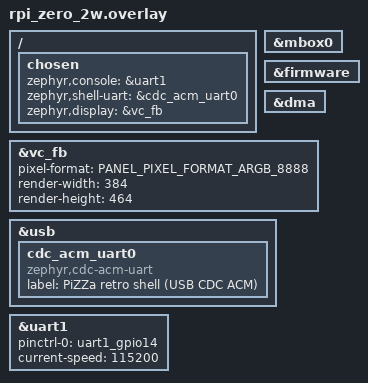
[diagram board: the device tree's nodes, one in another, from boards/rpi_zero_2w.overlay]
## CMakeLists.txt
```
# SPDX-License-Identifier: Apache-2.0
#
# PiZZa -- libretro frontend (apps/retro).
#
# A nanoarch-class libretro frontend over the sdl2shim seams: the 6
# libretro callbacks map onto s2s_present_* / s2s_audio_* / the shim
# event queue, and the core is (for M0) statically linked into the
# image -- the RetroArch console fused-binary model. llext-loaded
# cores arrive at M2.
#
# Core: libretro-2048 (public domain), consumed as an untouched
# upstream tree via the LIBRETRO_2048_SRC_DIR env, like minivmac's
# MINIVMAC_SRC_DIR. Pure C -- no C++ toolchain flags needed.

cmake_minimum_required(VERSION 3.20.0)

find_package(Zephyr REQUIRED HINTS $ENV{ZEPHYR_BASE})
project(pizza_retro LANGUAGES C)

# sample_usbd helper for the USB CDC ACM shell on hardware boards.
if(CONFIG_USB_DEVICE_STACK_NEXT)
  include(${ZEPHYR_BASE}/samples/subsys/usb/common/common.cmake)
endif()

if(NOT DEFINED ENV{LIBRETRO_2048_SRC_DIR})
  message(FATAL_ERROR
    "retro: set LIBRETRO_2048_SRC_DIR to a libretro-2048 checkout "
    "(git clone https://github.com/libretro/libretro-2048)")
endif()
set(CORE_DIR $ENV{LIBRETRO_2048_SRC_DIR})

# The non-cairo software renderer build: 3 TUs, XRGB8888.
set(RETRO_CORE_SRC
  ${CORE_DIR}/libretro.c
  ${CORE_DIR}/game_noncairo.c
  ${CORE_DIR}/game_shared.c
)

# ── shared shim (apps/lib/sdl2shim): CORE group only ────────────────
# The frontend makes no SDL draw calls; it consumes the event queue
# (SDL_PollEvent/SDL_GetKeyboardState) so every existing input
# producer (scripted, CDC shell, btinput) works unchanged.
include(${CMAKE_CURRENT_SOURCE_DIR}/../lib/sdl2shim/sdl2shim.cmake)

set(RETRO_SRC
  src/main.c
  src/retro_frontend.c
  src/retro_vfs_stubs.c
  ${SDL2SHIM_CORE_SOURCES}
)

# Audio backend (lib-owned). 2048 emits no audio; shim_stub.c still
# delegates to the s2s_audio_* seam, so a backend TU must link.
if(CONFIG_SDL2SHIM_AUDIO_HDMI)
  list(APPEND RETRO_SRC ${SDL2SHIM_AUDIO_HDMI_SOURCES})
else()
  list(APPEND RETRO_SRC ${SDL2SHIM_AUDIO_NONE})
endif()

# USB device stack bring-up (lib).
if(CONFIG_USB_DEVICE_STACK_NEXT)
  list(APPEND RETRO_SRC ${SDL2SHIM_USB})
endif()

# `retro` shell command set -- interactive retropad injection over CDC.
if(CONFIG_SHELL)
  list(APPEND RETRO_SRC src/retro_shell.c)
endif()

# Frame present backend (app-local, as for every shim consumer).
if(CONFIG_RETRO_PRESENT_DISPLAY)
  list(APPEND RETRO_SRC src/retro_present_display.c)
elseif(CONFIG_RETRO_PRESENT_SEMIHOST)
  list(APPEND RETRO_SRC src/retro_present_semihost.c)
else()
  list(APPEND RETRO_SRC src/retro_present_none.c)
endif()

# Scripted synthetic input -- title -> game -> moves timeline for the
# qemu sim gate.
if(CONFIG_RETRO_SCRIPTED_INPUT)
  list(APPEND RETRO_SRC src/retro_scripted.c)
endif()

# BT HID input (pad/keyboard) via apps/lib/btinput -- rpi_zero_2w only
# (boards/rpi_zero_2w.conf sets CONFIG_BTINPUT; qemu has no radio).
if(CONFIG_BTINPUT)
  include(${CMAKE_CURRENT_SOURCE_DIR}/../lib/btinput/btinput.cmake)
  # The BT patchram (.hcd) is a gitignored vendor blob (PROVENANCE.md).
  # Fail LOUDLY if missing: an empty-patchram image wedges the controller
  # at runtime (Download_Minidriver with nothing to launch).
  if(NOT CONFIG_AIROC_CUSTOM_FIRMWARE_HCD_BLOB)
    message(FATAL_ERROR
      "retro+BTINPUT: CONFIG_AIROC_CUSTOM_FIRMWARE_HCD_BLOB is unset")
  endif()
  set(_bt_blob "${CONFIG_AIROC_CUSTOM_FIRMWARE_HCD_BLOB}")
  if(NOT IS_ABSOLUTE "${_bt_blob}")
    set(_bt_blob "${CMAKE_CURRENT_SOURCE_DIR}/${_bt_blob}")
  endif()
  if(NOT EXISTS "${_bt_blob}")
    message(FATAL_ERROR
      "retro+BTINPUT: BT patchram not found:\n  ${_bt_blob}\n"
      "It is gitignored (vendor blob) -- fetch it per "
      "apps/lib/btinput/firmware/PROVENANCE.md before building.")
  endif()
  target_sources(app PRIVATE ${BTINPUT_SOURCES} src/retro_btinput.c)
  target_include_directories(app PRIVATE ${BTINPUT_INCLUDE_DIRS})
endif()

target_sources(app PRIVATE
  ${RETRO_CORE_SRC}
  ${RETRO_SRC}
)

target_include_directories(app PRIVATE
  ${SDL2SHIM_INCLUDE_DIRS}
  ${CORE_DIR}
  ${CORE_DIR}/libretro-common/include
  src
)

# The vendored core trips warnings its desktop builds silence.
set_source_files_properties(${RETRO_CORE_SRC} PROPERTIES COMPILE_OPTIONS
  "-Wno-unused-variable;-Wno-unused-parameter;-Wno-missing-field-initializers;-Wno-double-promotion;-Wno-missing-prototypes;-Wno-unused-but-set-variable"
)
```

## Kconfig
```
# SPDX-License-Identifier: Apache-2.0
#
# PiZZa libretro frontend -- app options.

# SAMPLE_USBD_* options for sample_usbd_init.c on boards with the USB
# device stack.
source "samples/subsys/usb/common/Kconfig.sample_usbd"

# Shared shim: audio-backend choice + SDL2SHIM log module.
rsource "../lib/sdl2shim/Kconfig"
# BT HID input (pad/keyboard/mouse) -- enabled per-board (rpi_zero_2w).
rsource "../lib/btinput/Kconfig"

menu "PiZZa libretro frontend"

choice RETRO_CORE_SOURCE
	prompt "libretro core source"
	default RETRO_CORE_STATIC

config RETRO_CORE_STATIC
	bool "Statically linked core (fused binary, RetroArch console model)"

config RETRO_CORE_LLEXT_EMBED
	bool "llext core embedded in the image (buf loader; sim)"
	depends on LLEXT

config RETRO_CORE_LLEXT_FS
	bool "llext core from the filesystem (fs loader; SD card)"
	depends on LLEXT && FILE_SYSTEM

endchoice

config RETRO_CORE_LLEXT_PATH
	string "Filesystem path of the core llext"
	depends on RETRO_CORE_LLEXT_FS
	default "/SD:/cores/2048.llext"

config RETRO_STORAGE_MOUNT
	string "Storage volume the frontend mounts (cores + saves)"
	depends on RETRO_CORE_LLEXT_FS
	default "/SD:"

config RETRO_MENU
	bool "Launcher menu (scan a cores dir, pick + swap in-process)"
	depends on RETRO_CORE_LLEXT_FS
	default y
	help
	  M4: on boot show a picker of the *.llext cores in
	  RETRO_MENU_DIR; launching one binds + runs it; the L+R pad
	  chord or `retro menu` tears it down and returns to the picker.
	  Without this the frontend runs the single RETRO_CORE_LLEXT_PATH
	  core forever (M3 behavior).

config RETRO_MENU_DIR
	string "Directory scanned for core llext files"
	depends on RETRO_MENU
	default "/SD:/cores"

config RETRO_MENU_WIDTH
	int "Launcher render width (match the board's virtual FB)"
	depends on RETRO_MENU
	default 640

config RETRO_MENU_HEIGHT
	int "Launcher render height (match the board's virtual FB)"
	depends on RETRO_MENU
	default 480

config RETRO_QEMU_RAMDISK_SEED
	bool "Seed the qemu ram-disk with embedded cores (sim menu test)"
	depends on RETRO_CORE_LLEXT_FS && DISK_DRIVER_RAM
	default n
	help
	  qemu has no SD: this writes cores .incbin'd into the image onto
	  the formatted ram-disk at boot so the launcher's fs scan + swap
	  exercises the exact HW path.

config RETRO_LLEXT_CYCLE_TEST
	int "Frames per bind cycle before unload/reload (0 = run forever)"
	default 0
	help
	  M2 gate: run N frames, tear the core down (unload_game, deinit,
	  llext unload), and let main() relaunch the frontend, which
	  reloads the core from scratch. The llext heap watermark is
	  logged pre-bind/post-unbind; allocated bytes must return to
	  baseline every cycle.

choice RETRO_PRESENT_BACKEND
	prompt "Frame present backend"
	default RETRO_PRESENT_DISPLAY if DISPLAY
	default RETRO_PRESENT_NONE

config RETRO_PRESENT_DISPLAY
	bool "Zephyr display API (bcm2835_fb + HVS scaling on hardware)"
	depends on DISPLAY

config RETRO_PRESENT_NONE
	bool "Drop frames (link/sim bring-up)"

config RETRO_PRESENT_SEMIHOST
	bool "Semihosting PPM capture (qemu sim gates)"
	depends on SEMIHOST

endchoice

config RETRO_CAPTURE_EVERY
	int "Capture every Nth presented frame (0 = first frame only)"
	depends on RETRO_PRESENT_SEMIHOST
	default 0

config RETRO_SCRIPTED_INPUT
	bool "Drive the core from the scripted synthetic input timeline"
	default n

module = RETRO
module-str = retro
source "subsys/logging/Kconfig.template.log_config"

endmenu

source "Kconfig.zephyr"
```

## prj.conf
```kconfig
# SPDX-License-Identifier: Apache-2.0
#
# Common config for the PiZZa libretro frontend. Per-board overrides
# (display, USB, semihost capture) live in boards/<board>.conf.

CONFIG_PRINTK=y
CONFIG_BOOT_BANNER=y

# Keep printk() synchronous so boot-time logging lands on the console
# even when the run loop is busy.
CONFIG_LOG_PRINTK=n

# picolibc's errno needs TLS -- same stanza as every shim consumer.
CONFIG_TOOLCHAIN_CROSS_COMPILE_SUPPORTS_THREAD_LOCAL_STORAGE=y
CONFIG_THREAD_LOCAL_STORAGE=y

# Heap: cores malloc from the FRONTEND's arena (malloc is an exported
# symbol), so size for the hungriest core. sokoban wants ~3.5 MB
# (640x480 backing + Game object + textures); Doom's zone allocator
# Z_Malloc's its whole ~24 MB heap from here. 32 MiB covers Doom with
# headroom; KERNEL_VM_SIZE is already 64 MB on both boards.
CONFIG_COMMON_LIBC_MALLOC_ARENA_SIZE=33554432

# retro_run + the core execute on the Zephyr main thread.
CONFIG_MAIN_STACK_SIZE=65536

CONFIG_FPU=y
CONFIG_STACK_SENTINEL=y
CONFIG_ASSERT=y
```

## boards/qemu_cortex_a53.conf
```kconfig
# SPDX-License-Identifier: Apache-2.0
#
# qemu_cortex_a53 -- the SIM target. No display hardware: frames leave
# the guest as PPM files via semihosting (retro_present_semihost.c);
# the scripted timeline drives title -> game -> D-pad moves.

# Run the emulated CPU at wall speed (fleet-standard: -icount stretches
# software rendering badly in wall-clock).
CONFIG_QEMU_ICOUNT=n

# The board defaults the kernel VM window to 8 MB; the 16 MiB malloc
# arena pushes the llext heap past it and the W^X permission pass
# asserts (mmu.h "invalid virtual address region"). 64 MB covers it.
CONFIG_KERNEL_VM_SIZE=0x4000000

CONFIG_SEMIHOST=y
CONFIG_RETRO_PRESENT_SEMIHOST=y
CONFIG_RETRO_CAPTURE_EVERY=30
CONFIG_RETRO_SCRIPTED_INPUT=y

# ── M2: llext-loaded core (embedded blob -- qemu has no SD) ─────────
# The .llext comes from core2048/ (west build -t core2048), named by
# the RETRO_CORE_LLEXT env at build time.
CONFIG_LLEXT=y
CONFIG_LLEXT_TYPE_ELF_RELOCATABLE=y
CONFIG_LLEXT_IMPORT_ALL_GLOBALS=y
CONFIG_LLEXT_HEAP_SIZE=4096
CONFIG_RETRO_CORE_LLEXT_EMBED=y

# Cycle test: 300 frames (~5 s) per bind, then unload + reload; the
# llext heap watermark is logged each cycle and must hold a baseline.
CONFIG_RETRO_LLEXT_CYCLE_TEST=300
CONFIG_SYS_HEAP_RUNTIME_STATS=y

# Synchronous shim logging on the emulated console.
CONFIG_LOG=y
CONFIG_LOG_MODE_MINIMAL=y
CONFIG_RETRO_LOG_LEVEL_DBG=y
```

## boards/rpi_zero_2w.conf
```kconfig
# SPDX-License-Identifier: Apache-2.0
#
# Raspberry Pi Zero 2 W (BCM2710, Cortex-A53, AArch64) -- libretro
# frontend. Console + logs on the mini-UART, interactive shell
# (`retro key ...`) on USB CDC ACM, HDMI via the VC firmware
# framebuffer with HVS scaling. No audio (the 2048 core emits none;
# the audio ring lands with the first audible core).

CONFIG_BOOT_DELAY=200

# ── M2: llext-loaded core from the SD FAT ───────────────────────────
# 2048.llext lives at /SD:/cores/2048.llext (build core2048/ for THIS
# board and copy it there). 64 KiB MMU pages round every ELF region up,
# so the heap floor is N regions x 64 KiB; 4 MiB covers small cores
# with headroom. RODATA_NO_RELOC requires !MMU -- force off (the
# Arduino-loader lesson).
CONFIG_LLEXT=y
CONFIG_LLEXT_TYPE_ELF_RELOCATABLE=y
CONFIG_LLEXT_IMPORT_ALL_GLOBALS=y
CONFIG_LLEXT_HEAP_SIZE=4096
CONFIG_LLEXT_RODATA_NO_RELOC=n
CONFIG_RETRO_CORE_LLEXT_FS=y

# The default kernel VM window is 8 MB (0x200000..0xA00000). The 16 MiB
# malloc arena + 4 MiB llext heap push the image's .bss/.noinit (incl.
# the llext heap the loader W^X-remaps) past that window, so
# k_mem_update_flags asserts "invalid virtual address region" mid-load.
# 64 MB covers the frontend + the biggest cores with headroom (SRAM is
# 256 MB). Same fix as the qemu board conf.
CONFIG_KERNEL_VM_SIZE=0x4000000

# VC mailbox + firmware (framebuffer alloc chain).
CONFIG_RASPBERRYPI_FIRMWARE=y

# HDMI display via VC firmware FB, ARGB_8888. The core's frame is
# centered in the 384x464 virtual FB (384*4 = 1536 B/row, 64-byte
# aligned for the FB driver's contiguous-DMA fast path); HVS scales
# to the monitor's native mode.
CONFIG_DISPLAY=y
CONFIG_BCM2835_FB=y

# BCM2835 DMA -- FB driver claims a channel for the backbuffer blit.
CONFIG_DMA=y
CONFIG_DMA_BCM2835=y

# USB CDC ACM shell, same shape as PizzaShell / wipeout / SDLPoP.
CONFIG_USB_DEVICE_STACK_NEXT=y
CONFIG_UDC_DWC2=y
CONFIG_UDC_DWC2_DMA=n
CONFIG_SERIAL=y
CONFIG_USBD_CDC_ACM_CLASS=y
CONFIG_CDC_ACM_SERIAL_INITIALIZE_AT_BOOT=n
CONFIG_SAMPLE_USBD_PRODUCT="PiZZa retro -- rpi_zero_2w"
CONFIG_SAMPLE_USBD_MANUFACTURER="jetpax/PiZZa"
CONFIG_SAMPLE_USBD_PID=0xCAFE
CONFIG_USBD_THREAD_STACK_SIZE=4096
CONFIG_UDC_DWC2_STACK_SIZE=4096

CONFIG_SHELL=y
CONFIG_SHELL_BACKEND_SERIAL=y
CONFIG_KERNEL_SHELL=y
CONFIG_SHELL_STACK_SIZE=8192
CONFIG_SHELL_VT100_COMMANDS=y
CONFIG_SHELL_HISTORY=y
CONFIG_SHELL_TAB=y
CONFIG_SHELL_LOG_BACKEND=n

# Logging on the board console (mini-UART), off the shell prompt.
CONFIG_LOG=y
CONFIG_LOG_BUFFER_SIZE=16384
CONFIG_LOG_BACKEND_UART=y
CONFIG_LOG_MODE_DEFERRED=y
CONFIG_USBD_CDC_ACM_LOG_LEVEL_WRN=y
CONFIG_USBD_LOG_LEVEL_INF=y
CONFIG_UDC_DRIVER_LOG_LEVEL_WRN=y

# ── Bluetooth HID input (8BitDo pad -> retropad) ─────────────────────
# Stack, host profile and connection policy all live in apps/lib/btinput;
# config mirrors the HW-proven minivmac/DOSBox/sokoban bring-up. The pad
# keymap (K-mode usages -> frontend scancodes) is in retro_btinput.c.
CONFIG_BTINPUT=y
CONFIG_BTINPUT_HOGP=y
CONFIG_BTINPUT_SEAM_SDL=y
CONFIG_BTINPUT_MANAGER=y
# Self-heal on an AIROC controller wedge (rescue-page HCI assert) with a
# clean cold reboot instead of a hung appliance -- rescue-page backoff
# already makes the wedge rare; this covers the residual.
CONFIG_BTINPUT_WEDGE_REBOOT=y

CONFIG_BT=y
CONFIG_BT_CLASSIC=y
CONFIG_BT_DEVICE_NAME="PiZZa"
CONFIG_BT_MAX_PAIRED=8
CONFIG_BT_MAX_CONN=3
# The 8BitDo's fw is legacy-only SMP; Just Works is the accepted trust model.
CONFIG_BT_SMP_SC_PAIR_ONLY=n
# The 4.2 controller has 1M PHY only; skip the doomed LE Set PHY attempt.
CONFIG_BT_AUTO_PHY_UPDATE=n

# Infineon AIROC patchram: this unit is the Synaptics 43436S module
# (BT ROM = 43430A1). Blob is gitignored; PROVENANCE.md has the fetch.
CONFIG_BT_AIROC=y
CONFIG_BT_AIROC_CUSTOM=y
CONFIG_AIROC_CUSTOM_FIRMWARE_HCD_BLOB="../lib/btinput/firmware/SYN43430A1.hcd"

# Bond persistence: settings FILE backend on the SD FAT (the manager
# mounts /SD:). MKFS stays off -- the card is PiZZa-imaged.
CONFIG_BT_SETTINGS=y
CONFIG_SETTINGS=y
CONFIG_SETTINGS_FILE=y
CONFIG_SETTINGS_FILE_PATH="/SD:/bt/settings"
CONFIG_DISK_ACCESS=y
CONFIG_DISK_DRIVERS=y
CONFIG_SDMMC_SUBSYS=y
CONFIG_FILE_SYSTEM=y
CONFIG_FAT_FILESYSTEM_ELM=y
CONFIG_FS_FATFS_LFN=y
CONFIG_FILE_SYSTEM_MKFS=n
# FS_FATFS_MOUNT_MKFS defaults Y and would REFORMAT (wipe) the SD on
# any mount failure -- the minivmac Phase-6 near-miss. Force it off.
CONFIG_FS_FATFS_MOUNT_MKFS=n

# ELM FatFs is NOT thread-safe by default; the bond store alone has two
# FatFs users (btinput manager thread + system workqueue for settings
# saves). Per-volume mutex + LFN buffer on stack.
CONFIG_FS_FATFS_REENTRANT=y
CONFIG_FS_FATFS_LFN_MODE_STACK=y

# aarch64: BT stack defaults are Cortex-M sized; P-256 on the long WQ
# needs 8K frames (instruction-abort class otherwise).
CONFIG_BT_LONG_WQ_STACK_SIZE=8192
CONFIG_BT_RX_STACK_SIZE=8192
CONFIG_BT_HCI_TX_STACK_SIZE_WITH_PROMPT=y
CONFIG_BT_HCI_TX_STACK_SIZE=4096
CONFIG_SYSTEM_WORKQUEUE_STACK_SIZE=8192
CONFIG_THREAD_NAME=y

# Bond hygiene (HW-proven on minivmac): let a re-pairing peer whose new
# IRK resolves an existing bond replace it instead of being refused, and
# allow JW-over-JW overwrites (JW has no MITM protection anyway).
CONFIG_BT_ID_UNPAIR_MATCHING_BONDS=y
CONFIG_BT_SMP_ALLOW_UNAUTH_OVERWRITE=y
```

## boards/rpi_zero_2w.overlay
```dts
/*
 * SPDX-License-Identifier: Apache-2.0
 *
 * PiZZa libretro frontend overlay for rpi_zero_2w.
 *
 *   - &mbox0 + &firmware: VC mailbox + property tags (FB alloc).
 *   - &vc_fb: HDMI framebuffer at the monitor's EDID-negotiated
 *     scanout mode. The virtual FB is 384x464: the 2048 core's native
 *     376x464 frame is CENTERED into it by retro_present_display.c
 *     (384 * 4 = 1536 bytes/row, 64-byte aligned, so the FB driver's
 *     contiguous-DMA fast path engages; 376 * 4 = 1504 is not). The
 *     VideoCore HVS scales the virtual FB to the cable on the fly --
 *     the proven Jet / wipeout / Doom / SDLPoP / sokoban trick.
 *   - &dma: BCM2835 DMA for the backbuffer->fb blit.
 *   - &usb + cdc_acm child: USB CDC ACM shell endpoint.
 *   - mini-UART (uart1) console + LOG target, PiZZa convention.
 */

#include <zephyr/dt-bindings/display/panel.h>

&mbox0 {
	status = "okay";
};

&firmware {
	status = "okay";
};

&dma {
	status = "okay";
};

&vc_fb {
	pixel-format = <PANEL_PIXEL_FORMAT_ARGB_8888>;
	render-width = <384>;
	render-height = <464>;
	status = "okay";
};

&usb {
	status = "okay";

	cdc_acm_uart0: cdc_acm_uart0 {
		compatible = "zephyr,cdc-acm-uart";
		label = "PiZZa retro shell (USB CDC ACM)";
	};
};

/ {
	chosen {
		zephyr,console = &uart1;
		zephyr,shell-uart = &cdc_acm_uart0;
		zephyr,display = &vc_fb;
	};
};

&uart1 {
	pinctrl-names = "default";
	pinctrl-0 = <&uart1_gpio14>;
	status = "okay";
	current-speed = <115200>;
};
```

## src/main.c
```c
/*
 * SPDX-License-Identifier: Apache-2.0
 *
 * PiZZa libretro frontend -- Zephyr entry point.
 */

#include <zephyr/kernel.h>
#include <stdio.h>

#include "sdl2shim.h"
#include "retro_frontend.h"
#include "retro_core.h"

#ifdef CONFIG_RETRO_MENU
#include "retro_menu.h"
#endif

#ifdef CONFIG_RETRO_QEMU_RAMDISK_SEED
#include "retro_qemu_seed.h"
#endif

#ifdef CONFIG_BTINPUT
void retro_btinput_start(void);
#endif

int main(void)
{
	printf("[retro] PiZZa libretro frontend, board %s\n", CONFIG_BOARD);

#ifdef CONFIG_RETRO_QEMU_RAMDISK_SEED
	retro_qemu_seed();
#endif

	if (IS_ENABLED(CONFIG_RETRO_SCRIPTED_INPUT)) {
		s2s_scripted_input_start();
	}

#ifdef CONFIG_BTINPUT
	retro_btinput_start();
#endif

#ifdef CONFIG_RETRO_MENU
	/* Launcher: pick a core, run it until the user asks for the menu
	 * (L+R chord / `retro menu`), then reload the picker. A bind/load
	 * failure falls straight back to the menu.
	 */
	for (;;) {
		static char path[128];

		if (retro_menu_run(path, sizeof(path)) == 0) {
			retro_core_set_path(path);
			retro_frontend_run();
		} else {
			k_msleep(1000);
		}
	}
#else
	/* Single-core appliance: run forever; only a load failure returns
	 * (loud on the console), so retry.
	 */
	for (;;) {
		int rc = retro_frontend_run();

		printf("[retro] frontend exited: %d -- retrying\n", rc);
		k_msleep(2000);
	}
#endif
	return 0;
}
```

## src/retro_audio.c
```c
/*
 * SPDX-License-Identifier: Apache-2.0
 *
 * PiZZa libretro frontend -- audio bridge (audio_batch_cb -> HDMI MAI).
 *
 * libretro hands the frontend a core's mixed output through
 * audio_batch_cb; the proven HDMI-MAI backend (shim_audio_hdmi.c, linked
 * into this image by CONFIG_SDL2SHIM_AUDIO_HDMI) instead PULLS its samples
 * from an SDL-style callback on a feeder thread. This file is the SPSC
 * ring that joins the push side to the pull side:
 *
 *   core mixer -> glue s2s_audio_lr_pump -> audio_batch_cb  (PRODUCER,
 *     run thread) -> retro_audio_push -> [ring] -> drain_cb (CONSUMER,
 *     feeder thread) -> shim_audio_hdmi -> resample 44.1->48k -> IEC958
 *     -> DMA (DREQ 17) -> VC4 MAI -> HDMI audio packets
 *
 * Concurrency contract (desk-reviewed -- why no lock is needed):
 *   - Exactly one producer. audio_batch_cb runs only on the frontend run
 *     thread: retro_frontend_run_loaded's core.run() -> the core's
 *     retro_run -> s2s_audio_lr_pump -> this callback.
 *   - Exactly one consumer. drain_cb runs only on the shim_audio_hdmi
 *     feeder thread: feeder_fn -> audio_pump_fill_block -> game_source ->
 *     st.callback (held under the backend's SDL audio mutex, which our
 *     ring is independent of).
 *   - Single-producer / single-consumer, so free-running head/tail sample
 *     counters with release/acquire ordering are safe with no mutex. The
 *     board is UP (no SMP), where a compiler barrier alone would suffice;
 *     the atomics keep it correct if SMP is ever enabled.
 *   - The backend lives in THIS image, not a core llext, so there is no
 *     kernel-object donation concern (unlike shim_libretro.c). The core
 *     is byte-unchanged by this seam -- the wiring is frontend-internal.
 *
 * Rate is fixed 44.1 kHz S16 stereo: the sdl2shim-over-libretro glue pins
 * it, so the backend's 147:160 resampler is exact. A pure upstream
 * libretro core running at some other av_info sample_rate would push at
 * that rate and come out pitch-shifted -- variable-rate resample is M6.1.
 */

#include <stdio.h>
#include <string.h>

#include <zephyr/kernel.h>
#include <zephyr/sys/atomic.h>
#include <zephyr/sys/util.h>

#include "sdl2shim.h"
#include "retro_audio.h"

/* 16384 samples = 8192 stereo frames ~= 186 ms at 44.1 kHz. The producer
 * delivers one video frame's audio in a burst per retro_run (Doom: ~1260
 * frames every 28.6 ms) while the MAI feeder drains continuously; the run
 * loop paces off retro_audio_ring_fill() to hold the ring near a cushion
 * (RETRO_AUDIO_TARGET_FRAMES) so it never runs near-empty and the feeder
 * never underruns. The ring must hold the cushion + a full burst with
 * headroom. Power of two -> cheap mask wrap; even -> L/R channel alignment
 * survives the wrap since both cursors only ever move by even (whole-frame)
 * counts.
 */
#define RING_SAMPLES 16384u
#define RING_MASK    (RING_SAMPLES - 1u)

static int16_t ring[RING_SAMPLES];
static atomic_t r_head; /* total samples produced (free-running) */
static atomic_t r_tail; /* total samples consumed (free-running) */
static bool audio_ready;

/* Master gain in Q8 (256 = unity), applied as each sample enters the
 * ring -- the one point every core's mixed stream passes through, so it
 * is the RetroPiZZa-global volume. Boot value from Kconfig; `retro vol`
 * adjusts it live.
 */
static atomic_t gain_q8 = ATOMIC_INIT(256);

/* Consumer: the SDL audio callback the feeder thread pulls once per DMA
 * block. Copy up to `len` bytes from the ring, then pad any shortfall
 * with silence -- never stale audio, the same contract game_source in
 * shim_audio_hdmi.c already relies on.
 */
static void drain_cb(void *userdata, Uint8 *stream, int len)
{
	ARG_UNUSED(userdata);

	int16_t *out = (int16_t *)stream;
	size_t want = (size_t)len / sizeof(int16_t);
	uint64_t tail = (uint64_t)atomic_get(&r_tail);
	uint64_t head = (uint64_t)atomic_get(&r_head); /* acquire the producer's writes */
	size_t avail = (size_t)(head - tail);
	size_t take = MIN(want, avail);

	for (size_t i = 0; i < take; i++) {
		out[i] = ring[(size_t)(tail + i) & RING_MASK];
	}
	for (size_t i = take; i < want; i++) {
		out[i] = 0;
	}
	atomic_set(&r_tail, (atomic_val_t)(tail + take)); /* release the slots */
}

size_t retro_audio_push(const int16_t *data, size_t frames)
{
	if (!audio_ready || data == NULL || frames == 0) {
		return frames; /* consume-and-drop: nothing downstream */
	}

	size_t n = frames * 2u; /* interleaved stereo samples */
	uint64_t head = (uint64_t)atomic_get(&r_head);
	uint64_t tail = (uint64_t)atomic_get(&r_tail);
	size_t fill = (size_t)(head - tail);
	int32_t g = (int32_t)atomic_get(&gain_q8);

	/* Accept only up to the latency target (not ring capacity): the
	 * all-or-nothing reject is the glue producer's backpressure signal
	 * -- it retries the same chunk after a short sleep, so nothing is
	 * dropped, the MAI drain paces production, and audio lag stays
	 * bounded at ~TARGET frames (~35 ms) instead of the full ring.
	 */
	if (fill + n > RETRO_AUDIO_TARGET_FRAMES * 2u) {
		return 0;
	}

	for (size_t i = 0; i < n; i++) {
		int32_t s = ((int32_t)data[i] * g) >> 8;

		ring[(size_t)(head + i) & RING_MASK] =
			(int16_t)CLAMP(s, INT16_MIN, INT16_MAX);
	}
	atomic_set(&r_head, (atomic_val_t)(head + n)); /* publish after the writes */
	return frames;
}

void retro_audio_set_volume(unsigned int percent)
{
	if (percent > 200) {
		percent = 200;
	}
	atomic_set(&gain_q8, (atomic_val_t)(percent * 256U / 100U));
}

unsigned int retro_audio_get_volume(void)
{
	return (unsigned int)atomic_get(&gain_q8) * 100U / 256U;
}

int retro_audio_init(void)
{
	SDL_AudioSpec desired;

	retro_audio_set_volume(CONFIG_RETRO_AUDIO_GAIN_PERCENT);

	memset(&desired, 0, sizeof(desired));
	desired.freq = 44100;
	desired.format = AUDIO_S16SYS;
	desired.channels = 2;
	desired.samples = 1024; /* sizes desired.size only; the backend fixes its own blocks */
	desired.callback = drain_cb;
	desired.userdata = NULL;

	atomic_set(&r_head, 0);
	atomic_set(&r_tail, 0);

	if (s2s_audio_open(&desired, NULL) != 0) {
		printf("[retro-audio] HDMI audio unavailable: %s\n",
		       SDL_GetError());
		return -1;
	}

	audio_ready = true;
	s2s_audio_pause(0); /* start the feed; the ring stays silent until a core plays */
	printf("[retro-audio] HDMI MAI bridge open (44.1k S16 stereo)\n");
	return 0;
}
```

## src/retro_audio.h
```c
/*
 * SPDX-License-Identifier: Apache-2.0
 *
 * PiZZa libretro frontend -- audio bridge (public entry point).
 */

#ifndef PIZZA_RETRO_AUDIO_H
#define PIZZA_RETRO_AUDIO_H

#include <stdbool.h>
#include <stddef.h>
#include <stdint.h>

/* Ring accept limit, in 44.1 kHz stereo frames: push rejects once this
 * much is buffered, which is the glue producer's backpressure signal --
 * the MAI drain rate paces production and audio lag stays bounded at
 * ~35 ms.
 */
#define RETRO_AUDIO_TARGET_FRAMES 1536u

/* Open the HDMI-MAI audio backend and start its feeder. Call once at
 * boot (hardware only; qemu has no MAI). Returns 0, or negative if the
 * MAI path is unavailable (DVI sink / no HDMI display) -- the frontend
 * then simply runs silent.
 */
int retro_audio_init(void);

/* Producer seam: push `frames` of interleaved S16 stereo (44.1 kHz),
 * as handed to libretro's audio_batch callback, into the bridge ring.
 * Lock-free SPSC -- the core's audio producer is the sole producer, the
 * MAI feeder the sole consumer. All-or-nothing: returns `frames` when
 * accepted, 0 when the ring is full (the producer's backpressure signal
 * -- it retries the same chunk). Never blocks.
 */
size_t retro_audio_push(const int16_t *data, size_t frames);

/* RetroPiZZa-global master volume, percent of unity (0..200; >100
 * amplifies with clamping). Applied to every core's mixed stream as it
 * enters the bridge ring. Boot default = CONFIG_RETRO_AUDIO_GAIN_PERCENT;
 * `retro vol` adjusts live.
 */
void retro_audio_set_volume(unsigned int percent);
unsigned int retro_audio_get_volume(void);

#endif /* PIZZA_RETRO_AUDIO_H */
```

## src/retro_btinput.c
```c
/*
 * SPDX-License-Identifier: Apache-2.0
 *
 * PiZZa libretro frontend -- Bluetooth HID input (CONFIG_BTINPUT).
 *
 * The whole BT stack lives in apps/lib/btinput (manager = bring-up +
 * connection policy on its own thread; SDL seam = events into the
 * sdl2shim queue the frontend drains). This TU is only consumer
 * policy: remap the 8BitDo Micro's stock K-mode letters onto the
 * scancodes the frontend's joypad table reads, so the pad IS the
 * retropad. Any real BT keyboard passes through unmapped -- HID
 * usages are SDL scancodes 1:1, so its arrows/RETURN/TAB just work.
 */

#include <zephyr/kernel.h>

#include <SDL2/SDL.h>

#include "btinput.h"

/* 8BitDo Micro, K mode, stock map (usage set confirmed on the DOSBox
 * and sokoban ports). Frontend joypad table: arrows = d-pad,
 * RETURN = START, TAB = SELECT, Z = B, X = A, A = Y, S = X,
 * Q/W = L/R. For 2048: A starts/pauses, B continues after a win.
 * Home fires during the pad's power-off long-press and the four
 * provisional usages are uncertain, so they're pinned to P -- a
 * scancode the frontend joypad table does not read at all (inert).
 */
static const struct btinput_seam_key pad_map[] = {
	{ 0x06, SDL_SCANCODE_UP },     /* d-pad Up    (C)              */
	{ 0x07, SDL_SCANCODE_DOWN },   /* d-pad Down  (D)              */
	{ 0x08, SDL_SCANCODE_LEFT },   /* d-pad Left  (E)              */
	{ 0x09, SDL_SCANCODE_RIGHT },  /* d-pad Right (F)              */
	{ 0x0a, SDL_SCANCODE_RETURN }, /* A (G) -> START               */
	{ 0x0d, SDL_SCANCODE_TAB },    /* B (J) -> SELECT              */
	{ 0x0b, SDL_SCANCODE_Z },      /* X (H) -> retropad B          */
	{ 0x0c, SDL_SCANCODE_S },      /* Y (I) -> retropad X          */
	{ 0x12, SDL_SCANCODE_Q },      /* L (O) -> retropad L          */
	{ 0x11, SDL_SCANCODE_W },      /* R (N) -> retropad R          */
	{ 0x16, SDL_SCANCODE_P },      /* Home -> inert (power-off)    */
	{ 0x0e, SDL_SCANCODE_P },      /* provisional -> inert         */
	{ 0x0f, SDL_SCANCODE_P },      /* provisional -> inert         */
	{ 0x10, SDL_SCANCODE_P },      /* provisional -> inert         */
	{ 0x15, SDL_SCANCODE_P },      /* provisional -> inert         */
};

void retro_btinput_start(void)
{
	btinput_seam_sdl_set_keymap(pad_map, ARRAY_SIZE(pad_map));
	btinput_seam_sdl_set_bounds(376, 464);
	btinput_seam_sdl_attach();
	btinput_manager_start();
}
```

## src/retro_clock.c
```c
/*
 * SPDX-License-Identifier: Apache-2.0
 *
 * PiZZa libretro frontend -- ARM clock bump (rpi_zero_2w).
 *
 * The VideoCore firmware idles the Cortex-A53 at arm_freq_min (~600 MHz)
 * unless something requests the turbo clock; Zephyr runs no cpufreq
 * governor. A Doom-class core plus the inline audio mix (SFX + OPL synth)
 * needs more than one 600 MHz core-second per second (measured ~137% --
 * game ~19 ms + pump ~21 ms per 28.6 ms frame), so pin the A53 at its
 * rated 1.0 GHz at boot, the same SET_CLOCK_RATE bump the Jet / wipeout /
 * DOSBox / faux86 ports use.
 */

#include <zephyr/kernel.h>
#include <zephyr/device.h>
#include <zephyr/sys/printk.h>

#include "retro_clock.h"

#if defined(CONFIG_RASPBERRYPI_FIRMWARE)

#include <rpi_fw.h>

#define VC_CLOCK_ID_ARM 3U
#define ARM_TARGET_HZ   1000000000U

/* Not (yet) in rpi_fw.h: under-voltage / throttle status bits.
 * Response: bit0 under-voltage now, bit1 ARM freq capped, bit2 throttled;
 * bits 16-18 = the same has-occurred-since-boot latches.
 */
#define RETRO_FW_TAG_GET_THROTTLED 0x00030046U

void retro_bump_arm_clock(void)
{
	const struct device *fw = DEVICE_DT_GET_ONE(raspberrypi_bcm283x_firmware);

	if (!device_is_ready(fw)) {
		printk("[retro] VC firmware not ready -- ARM stays at idle clock\n");
		return;
	}

	uint32_t cur[2] = {VC_CLOCK_ID_ARM, 0U};

	rpi_fw_transfer(fw, RPI_FW_TAG_GET_CLOCK_RATE, cur, sizeof(cur));

	uint32_t req[3] = {VC_CLOCK_ID_ARM, ARM_TARGET_HZ, 0U /* skip_setting_turbo */};
	int err = rpi_fw_transfer(fw, RPI_FW_TAG_SET_CLOCK_RATE, req, sizeof(req));

	uint32_t post[2] = {VC_CLOCK_ID_ARM, 0U};

	rpi_fw_transfer(fw, RPI_FW_TAG_GET_CLOCK_RATE, post, sizeof(post));

	/* The set-point can lie: MEASURED is the PLL truth, and THROTTLED
	 * says why they might disagree (under-voltage refuses turbo).
	 */
	uint32_t meas[2] = {VC_CLOCK_ID_ARM, 0U};
	uint32_t thr[1] = {0U};

	rpi_fw_transfer(fw, RPI_FW_TAG_GET_CLOCK_MEASURED, meas, sizeof(meas));
	rpi_fw_transfer(fw, RETRO_FW_TAG_GET_THROTTLED, thr, sizeof(thr));

	printk("[retro] ARM clock: %u -> %u Hz (SET err=%d), measured %u Hz, throttled 0x%x\n",
	       (unsigned int)cur[1], (unsigned int)post[1], err,
	       (unsigned int)meas[1], (unsigned int)thr[0]);
}

#else /* no VC firmware (qemu) */

void retro_bump_arm_clock(void)
{
}

#endif
```

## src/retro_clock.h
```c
/*
 * SPDX-License-Identifier: Apache-2.0
 *
 * PiZZa libretro frontend -- ARM clock bump (no-op without VC firmware).
 */

#ifndef PIZZA_RETRO_CLOCK_H
#define PIZZA_RETRO_CLOCK_H

void retro_bump_arm_clock(void);

#endif /* PIZZA_RETRO_CLOCK_H */
```

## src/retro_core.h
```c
/*
 * SPDX-License-Identifier: Apache-2.0
 *
 * PiZZa libretro frontend -- core-binding seam.
 *
 * The frontend drives a core exclusively through this dispatch table.
 * Two binders (Kconfig choice):
 *   retro_core_static.c -- link-time symbols (fused binary, M0/M1)
 *   retro_core_llext.c  -- llext-loaded core (M2+): embedded blob via
 *                          buf loader (sim) or /SD: file via fs loader
 */

#ifndef PIZZA_RETRO_CORE_H
#define PIZZA_RETRO_CORE_H

#include <libretro.h>

struct retro_core_api {
	void (*set_environment)(retro_environment_t);
	void (*set_video_refresh)(retro_video_refresh_t);
	void (*set_audio_sample)(retro_audio_sample_t);
	void (*set_audio_sample_batch)(retro_audio_sample_batch_t);
	void (*set_input_poll)(retro_input_poll_t);
	void (*set_input_state)(retro_input_state_t);
	void (*init)(void);
	void (*deinit)(void);
	unsigned int (*api_version)(void);
	void (*get_system_info)(struct retro_system_info *);
	void (*get_system_av_info)(struct retro_system_av_info *);
	void (*set_controller_port_device)(unsigned int, unsigned int);
	void (*reset)(void);
	void (*run)(void);
	size_t (*serialize_size)(void);
	bool (*serialize)(void *, size_t);
	bool (*unserialize)(const void *, size_t);
	void (*cheat_reset)(void);
	void (*cheat_set)(unsigned int, bool, const char *);
	bool (*load_game)(const struct retro_game_info *);
	bool (*load_game_special)(unsigned int,
				  const struct retro_game_info *, size_t);
	void (*unload_game)(void);
	unsigned int (*get_region)(void);
	void *(*get_memory_data)(unsigned int);
	size_t (*get_memory_size)(unsigned int);
};

/* Fill the table (loading the core first if it is an llext).
 * Returns 0 on success.
 */
int retro_core_bind(struct retro_core_api *api);

/* Release the core (llext: teardown + unload + heap back to baseline;
 * static: no-op). The table is dead after this.
 */
void retro_core_unbind(void);

#endif /* PIZZA_RETRO_CORE_H */
```

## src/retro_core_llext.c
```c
/*
 * SPDX-License-Identifier: Apache-2.0
 *
 * PiZZa libretro frontend -- llext core binder (M2, the bridge).
 *
 * Loads the core as a relocatable llext and resolves the 25 retro_*
 * entry points into the dispatch table (CONFIG_LLEXT_IMPORT_ALL_GLOBALS
 * exposes them without any core-side EXPORT annotation, so the core
 * tree stays untouched). Two sources:
 *   CONFIG_RETRO_CORE_LLEXT_EMBED -- blob .incbin'd into rodata, buf
 *     loader (sim: qemu has no SD).
 *   CONFIG_RETRO_CORE_LLEXT_FS    -- CONFIG_RETRO_CORE_LLEXT_PATH on
 *     the SD FAT, fs loader; mounts /SD: if nothing else has yet.
 *
 * unbind() runs llext_teardown + llext_unload: every heap region is
 * refcount-freed, so bind/unbind cycles return the llext heap to
 * baseline -- the M2 gate.
 */

#include <zephyr/kernel.h>
#include <zephyr/logging/log.h>
#include <zephyr/llext/llext.h>
#include <zephyr/llext/buf_loader.h>
#include <zephyr/llext/fs_loader.h>
#ifdef CONFIG_RETRO_CORE_LLEXT_FS
#include <zephyr/fs/fs.h>
#include <stdlib.h>
#endif
#include <string.h>

#include "retro_core.h"

LOG_MODULE_REGISTER(retro_core, CONFIG_RETRO_LOG_LEVEL);

static struct llext *core_ext;

#ifdef CONFIG_RETRO_CORE_LLEXT_FS
#include "retro_storage.h"

/* The path to load. The launcher menu overrides it per selection via
 * retro_core_set_path(); empty = the build-time default.
 */
static char fs_path[128];

void retro_core_set_path(const char *path)
{
	if (path != NULL) {
		strncpy(fs_path, path, sizeof(fs_path) - 1);
		fs_path[sizeof(fs_path) - 1] = '\0';
	}
}

/* Read the whole .llext into a RAM buffer (caller frees). The fs loader
 * seek+reads per section/symbol/relocation, and on the SD card each op
 * pays FATFS + card latency -- ~1 minute for Doom's 1.1 MB core. One
 * sequential slurp here, then a TEMPORARY buf loader over RAM, cuts that
 * to a couple of seconds (the loader peeks RAM instead of hitting the
 * card thousands of times).
 */
static void *slurp_llext(const char *path, size_t *out_len)
{
	struct fs_dirent st;
	struct fs_file_t f;
	uint8_t *buf;
	size_t off = 0;

	if (fs_stat(path, &st) != 0 || st.type != FS_DIR_ENTRY_FILE) {
		LOG_ERR("llext: stat %s failed", path);
		return NULL;
	}
	buf = malloc(st.size);
	if (buf == NULL) {
		LOG_ERR("llext: alloc %zu for %s failed", (size_t)st.size, path);
		return NULL;
	}
	fs_file_t_init(&f);
	if (fs_open(&f, path, FS_O_READ) != 0) {
		LOG_ERR("llext: open %s failed", path);
		free(buf);
		return NULL;
	}
	while (off < (size_t)st.size) {
		ssize_t rd = fs_read(&f, buf + off, (size_t)st.size - off);

		if (rd <= 0) {
			break;
		}
		off += (size_t)rd;
	}
	fs_close(&f);

	if (off != (size_t)st.size) {
		LOG_ERR("llext: short read %s (%zu/%zu)", path, off,
			(size_t)st.size);
		free(buf);
		return NULL;
	}
	*out_len = (size_t)st.size;
	return buf;
}
#else
extern const uint8_t retro_core_blob_start[];
extern const uint8_t retro_core_blob_end[];

void retro_core_set_path(const char *path)
{
	(void)path;
}
#endif

static const void *find_sym_checked(const char *name, bool *ok)
{
	const void *p = llext_find_sym(&core_ext->exp_tab, name);

	if (!p) {
		LOG_ERR("llext: core does not export %s", name);
		*ok = false;
	}
	return p;
}

int retro_core_bind(struct retro_core_api *api)
{
	int rc;
	struct llext_load_param ldr_parm = LLEXT_LOAD_PARAM_DEFAULT;

#ifdef CONFIG_RETRO_CORE_LLEXT_FS
	rc = retro_storage_mount();
	if (rc != 0) {
		return rc;
	}

	const char *path = fs_path[0] ? fs_path : CONFIG_RETRO_CORE_LLEXT_PATH;

	LOG_INF("llext: loading %s", path);

	size_t blob_len = 0;
	void *fs_buf = slurp_llext(path, &blob_len);

	if (fs_buf == NULL) {
		return -EIO;
	}
	struct llext_buf_loader buf_ldr =
		LLEXT_TEMPORARY_BUF_LOADER(fs_buf, blob_len);
	struct llext_loader *ldr = &buf_ldr.loader;
#else
	size_t blob_len = retro_core_blob_end - retro_core_blob_start;
	struct llext_buf_loader buf_ldr =
		LLEXT_BUF_LOADER(retro_core_blob_start, blob_len);
	struct llext_loader *ldr = &buf_ldr.loader;

	LOG_INF("llext: loading embedded core (%zu bytes)", blob_len);
#endif

	rc = llext_load(ldr, "core", &core_ext, &ldr_parm);

#ifdef CONFIG_RETRO_CORE_LLEXT_FS
	/* TEMPORARY storage: llext has copied every region into its heap, so
	 * nothing points back into the slurp buffer -- free it now.
	 */
	free(fs_buf);
#endif

	if (rc != 0) {
		LOG_ERR("llext: load failed (%d)", rc);
		core_ext = NULL;
		return rc;
	}

	bool ok = true;

#define BIND(field, name)						\
	api->field = (__typeof__(api->field))				\
		find_sym_checked("retro_" name, &ok)

	BIND(set_environment,            "set_environment");
	BIND(set_video_refresh,          "set_video_refresh");
	BIND(set_audio_sample,           "set_audio_sample");
	BIND(set_audio_sample_batch,     "set_audio_sample_batch");
	BIND(set_input_poll,             "set_input_poll");
	BIND(set_input_state,            "set_input_state");
	BIND(init,                       "init");
	BIND(deinit,                     "deinit");
	BIND(api_version,                "api_version");
	BIND(get_system_info,            "get_system_info");
	BIND(get_system_av_info,         "get_system_av_info");
	BIND(set_controller_port_device, "set_controller_port_device");
	BIND(reset,                      "reset");
	BIND(run,                        "run");
	BIND(serialize_size,             "serialize_size");
	BIND(serialize,                  "serialize");
	BIND(unserialize,                "unserialize");
	BIND(cheat_reset,                "cheat_reset");
	BIND(cheat_set,                  "cheat_set");
	BIND(load_game,                  "load_game");
	BIND(load_game_special,          "load_game_special");
	BIND(unload_game,                "unload_game");
	BIND(get_region,                 "get_region");
	BIND(get_memory_data,            "get_memory_data");
	BIND(get_memory_size,            "get_memory_size");
#undef BIND

	if (!ok) {
		retro_core_unbind();
		return -ENOENT;
	}

	/* Run .preinit_array/.init_array (no-op for C cores; C++ cores
	 * need their static constructors before any entry point).
	 */
	rc = llext_bringup(core_ext);
	if (rc != 0) {
		LOG_ERR("llext: bringup failed (%d)", rc);
		retro_core_unbind();
		return rc;
	}

	LOG_INF("llext: core bound (%u exported symbols)",
		(unsigned int)core_ext->exp_tab.sym_cnt);
	return 0;
}

void retro_core_unbind(void)
{
	if (!core_ext) {
		return;
	}

	int rc = llext_teardown(core_ext);

	if (rc != 0) {
		LOG_WRN("llext: teardown rc=%d", rc);
	}

	rc = llext_unload(&core_ext);
	if (rc != 0) {
		LOG_WRN("llext: unload rc=%d", rc);
	}
	core_ext = NULL;
}
```

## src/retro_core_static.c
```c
/*
 * SPDX-License-Identifier: Apache-2.0
 *
 * PiZZa libretro frontend -- static core binder
 * (CONFIG_RETRO_CORE_STATIC): the core's retro_* symbols are linked
 * into the image (RetroArch console fused-binary model).
 */

#include "retro_core.h"

int retro_core_bind(struct retro_core_api *api)
{
	api->set_environment            = retro_set_environment;
	api->set_video_refresh          = retro_set_video_refresh;
	api->set_audio_sample           = retro_set_audio_sample;
	api->set_audio_sample_batch     = retro_set_audio_sample_batch;
	api->set_input_poll             = retro_set_input_poll;
	api->set_input_state            = retro_set_input_state;
	api->init                       = retro_init;
	api->deinit                     = retro_deinit;
	api->api_version                = retro_api_version;
	api->get_system_info            = retro_get_system_info;
	api->get_system_av_info         = retro_get_system_av_info;
	api->set_controller_port_device = retro_set_controller_port_device;
	api->reset                      = retro_reset;
	api->run                        = retro_run;
	api->serialize_size             = retro_serialize_size;
	api->serialize                  = retro_serialize;
	api->unserialize                = retro_unserialize;
	api->cheat_reset                = retro_cheat_reset;
	api->cheat_set                  = retro_cheat_set;
	api->load_game                  = retro_load_game;
	api->load_game_special          = retro_load_game_special;
	api->unload_game                = retro_unload_game;
	api->get_region                 = retro_get_region;
	api->get_memory_data            = retro_get_memory_data;
	api->get_memory_size            = retro_get_memory_size;
	return 0;
}

void retro_core_unbind(void)
{
}

void retro_core_set_path(const char *path)
{
	(void)path;
}
```

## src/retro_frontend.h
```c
/*
 * SPDX-License-Identifier: Apache-2.0
 *
 * PiZZa libretro frontend -- public entry point.
 */

#ifndef PIZZA_RETRO_FRONTEND_H
#define PIZZA_RETRO_FRONTEND_H

/* Bind callbacks, init the core, load no-content, then pace
 * retro_run() at the core's declared fps. Only returns on a load
 * failure.
 */
int retro_frontend_run(void);

#endif /* PIZZA_RETRO_FRONTEND_H */
```

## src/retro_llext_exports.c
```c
/*
 * SPDX-License-Identifier: Apache-2.0
 *
 * PiZZa libretro frontend -- symbol exports for llext cores.
 *
 * The exact undefined-symbol surface of 2048.llext (aarch64-...-nm -u),
 * exported from the frontend image so llext_load resolves them. Driven
 * empirically, NOT from grep -- extend when a new core's load log
 * reports unresolved symbols. The filestream/path stubs live in
 * retro_vfs_stubs.c and are exported here so cores share the frontend's
 * (refusing) VFS surface.
 */

#include <zephyr/kernel.h>
#include <zephyr/sys/printk.h>
#include <zephyr/llext/symbol.h>
#ifdef CONFIG_FILE_SYSTEM
#include <zephyr/fs/fs.h>
#endif

#include <stdio.h>
#include <stdlib.h>
#include <string.h>
#include <strings.h>
#include <ctype.h>
#include <math.h>
#include <time.h>

#include <streams/file_stream.h>
#include <file/file_path.h>

/* picolibc assert plumbing (assert() with no message variant). */
extern void __assert_no_args(void);

/* string.h / stdlib.h */
EXPORT_SYMBOL(memcpy);
EXPORT_SYMBOL(memset);
EXPORT_SYMBOL(strlen);
EXPORT_SYMBOL(strncmp);
EXPORT_SYMBOL(atoi);
EXPORT_SYMBOL(malloc);
EXPORT_SYMBOL(calloc);
EXPORT_SYMBOL(free);
EXPORT_SYMBOL(rand);
EXPORT_SYMBOL(srand);

/* stdio (tinystdio funnels the FILE* globals too) */
EXPORT_SYMBOL(fprintf);
EXPORT_SYMBOL(sprintf);
EXPORT_SYMBOL(vsprintf);
EXPORT_SYMBOL(stdout);
EXPORT_SYMBOL(stderr);

/* libm / time / assert */
EXPORT_SYMBOL(cos);
EXPORT_SYMBOL(time);
EXPORT_SYMBOL(__assert_no_args);

/* ── sokoban core additions (sdl2shim-over-libretro, C++) ──────── */

/* libc growth */
EXPORT_SYMBOL(cosf);
EXPORT_SYMBOL(sinf);
EXPORT_SYMBOL(memcmp);
EXPORT_SYMBOL(strcmp);
EXPORT_SYMBOL(printf);
EXPORT_SYMBOL(puts);
EXPORT_SYMBOL(snprintf);
EXPORT_SYMBOL(vsnprintf);

/* kernel: the glue's thread/sem/timer machinery + SDL timing. With
 * CONFIG_USERSPACE=n the k_* wrappers inline to z_impl_* calls, so
 * those are the actual imports.
 */
EXPORT_SYMBOL(printk);
EXPORT_SYMBOL(k_timer_init);
EXPORT_SYMBOL(sys_clock_cycle_get_64);
/* HW-only: with TIMER_READS_ITS_FREQUENCY_AT_RUNTIME the cycle rate
 * is this global, not a compile-time constant (qemu never links it).
 * The header extern (time_units.h) is scoped inside an inline fn, so
 * redeclare at file scope to export it. sys_clock_hw_cycles_per_sec()
 * / k_uptime / anything cycle-based reads it.
 */
#ifdef CONFIG_TIMER_READS_ITS_FREQUENCY_AT_RUNTIME
extern unsigned int z_clock_hw_cycles_per_sec;
EXPORT_SYMBOL(z_clock_hw_cycles_per_sec);
#endif
EXPORT_SYMBOL(z_impl_k_sem_init);
EXPORT_SYMBOL(z_impl_k_sem_give);
EXPORT_SYMBOL(z_impl_k_sem_take);
EXPORT_SYMBOL(z_impl_k_mutex_init);
EXPORT_SYMBOL(z_impl_k_mutex_lock);
EXPORT_SYMBOL(z_impl_k_mutex_unlock);
/* Doom OPL music glue (opl_glue.c) wraps SDL cond vars over these. The
 * OPL driver only uses mutexes at runtime (the cond path is Chocolate's
 * hardware-detect delay, never taken here), but the symbols are still
 * referenced by the compiled glue, so they must resolve at llext load.
 * k_condvar has no TLS/name field, so its layout matches the core's.
 */
EXPORT_SYMBOL(z_impl_k_condvar_init);
EXPORT_SYMBOL(z_impl_k_condvar_signal);
EXPORT_SYMBOL(z_impl_k_condvar_wait);
EXPORT_SYMBOL(z_impl_k_sleep);
EXPORT_SYMBOL(z_impl_k_thread_create);
EXPORT_SYMBOL(z_impl_k_thread_join);
EXPORT_SYMBOL(z_impl_k_thread_abort);
EXPORT_SYMBOL(z_impl_k_thread_name_set);
EXPORT_SYMBOL(z_impl_k_timer_start);
EXPORT_SYMBOL(z_impl_k_timer_stop);
EXPORT_SYMBOL(z_impl_k_uptime_ticks);

/* sdl2shim-over-libretro donations: ALL kernel objects a wrapped-app
 * core needs live HERE, in the image, never in the core. struct
 * k_thread/k_sem/k_mutex layouts depend on kernel config; the core's
 * minimal TLS-free build disagrees with this image's, so core-side
 * allocation gets overrun when the frontend kernel initializes the
 * object with its own sizeof (the M3 semaphore-zeroing incident).
 */
K_THREAD_STACK_DEFINE(s2s_lr_app_stack, CONFIG_SDL2SHIM_LIBRETRO_APP_STACK);
const size_t s2s_lr_app_stack_size = K_THREAD_STACK_SIZEOF(s2s_lr_app_stack);
struct k_thread s2s_lr_app_thread;
struct k_sem s2s_lr_sem_run;
struct k_sem s2s_lr_sem_frame;
struct k_mutex s2s_lr_audio_mutex;
EXPORT_SYMBOL(s2s_lr_app_stack);
EXPORT_SYMBOL(s2s_lr_app_stack_size);
EXPORT_SYMBOL(s2s_lr_app_thread);
EXPORT_SYMBOL(s2s_lr_sem_run);
EXPORT_SYMBOL(s2s_lr_sem_frame);
EXPORT_SYMBOL(s2s_lr_audio_mutex);
/* Audio producer thread (M6.6): the glue mixes the game's audio on this
 * dedicated thread -- above the game in priority, so audio production
 * preempts game compute instead of starving behind it -- and pushes to the
 * frontend's batch callback. Donated for the same layout reasons as above.
 */
K_THREAD_STACK_DEFINE(s2s_lr_audio_stack, 16384);
const size_t s2s_lr_audio_stack_size = K_THREAD_STACK_SIZEOF(s2s_lr_audio_stack);
struct k_thread s2s_lr_audio_thread;
EXPORT_SYMBOL(s2s_lr_audio_stack);
EXPORT_SYMBOL(s2s_lr_audio_stack_size);
EXPORT_SYMBOL(s2s_lr_audio_thread);

/* frontend VFS stubs (retro_vfs_stubs.c) */
EXPORT_SYMBOL(filestream_open);
EXPORT_SYMBOL(filestream_close);
EXPORT_SYMBOL(filestream_read);
EXPORT_SYMBOL(filestream_write);
EXPORT_SYMBOL(filestream_seek);
EXPORT_SYMBOL(filestream_tell);
EXPORT_SYMBOL(filestream_vfs_init);
EXPORT_SYMBOL(fill_pathname_join);
EXPORT_SYMBOL(path_is_valid);

/* ── M5 content cores: the fs surface a core's stdio layer binds to ──
 * A need_fullpath core (fstest, Doom) defines its own fopen/fread/...
 * over these (Approach 2: an imported picolibc fopen would funnel to
 * the frontend's open(), never the core's -- so the core owns stdio and
 * calls straight through to fs_*). Exporting fs_seek/fs_tell also
 * anchors them into the image (the frontend itself only reads
 * sequentially).
 */
#ifdef CONFIG_FILE_SYSTEM
EXPORT_SYMBOL(fs_open);
EXPORT_SYMBOL(fs_close);
EXPORT_SYMBOL(fs_read);
EXPORT_SYMBOL(fs_write);
EXPORT_SYMBOL(fs_seek);
EXPORT_SYMBOL(fs_tell);
EXPORT_SYMBOL(fs_stat);
EXPORT_SYMBOL(fs_mkdir);
EXPORT_SYMBOL(fs_unlink);
#endif

/* ── Doom core additions (sdl2-doom engine libc surface) ──────────
 * The empirical set doom.llext imports that the frontend image does not
 * otherwise pull in (nm -u doom.llext minus the image's defined globals;
 * the rest -- memmove/realloc/strchr/strncpy/exit/vfprintf... -- are
 * already linked and resolve via LLEXT_IMPORT_ALL_GLOBALS). These are
 * exported for the game's config/DEH/string paths; the WAD read path
 * itself binds to the core's own fs-backed stdio (doom_core_fs.c).
 */
extern const char _ctype_b[]; /* picolibc ctype table (isX inlines) */
/* POSIX, not exposed by the default picolibc feature set here. */
extern char *strdup(const char *s);
extern int putenv(char *string);
EXPORT_SYMBOL(_ctype_b);
EXPORT_SYMBOL(atexit);
EXPORT_SYMBOL(atof);
EXPORT_SYMBOL(putenv);
EXPORT_SYMBOL(remove);
EXPORT_SYMBOL(fflush);
EXPORT_SYMBOL(fgets);
EXPORT_SYMBOL(fputc);
EXPORT_SYMBOL(putchar);
EXPORT_SYMBOL(sscanf);
EXPORT_SYMBOL(vfprintf);
EXPORT_SYMBOL(strcasecmp);
EXPORT_SYMBOL(strncasecmp);
EXPORT_SYMBOL(strdup);
EXPORT_SYMBOL(strstr);
EXPORT_SYMBOL(tolower);
EXPORT_SYMBOL(toupper);
/* Libc the frontend doesn't itself reference (so absent from the image
 * and unreachable via IMPORT_ALL_GLOBALS); EXPORT_SYMBOL anchors them.
 * exit/strchr the frontend never calls; realloc/strrchr/strncpy/memmove
 * it does, but export them too so the set is explicit and load-proof.
 */
EXPORT_SYMBOL(exit);
EXPORT_SYMBOL(realloc);
EXPORT_SYMBOL(memmove);
EXPORT_SYMBOL(strchr);
EXPORT_SYMBOL(strrchr);
EXPORT_SYMBOL(strncpy);
/* OPL music (Chocolate opl.c / i_oplmusic.c) reads env overrides for the
 * OPL I/O port and MIDI options; with no environment getenv returns NULL
 * and the defaults apply. The frontend never calls getenv itself, so
 * anchor it into the image. */
EXPORT_SYMBOL(getenv);
```
